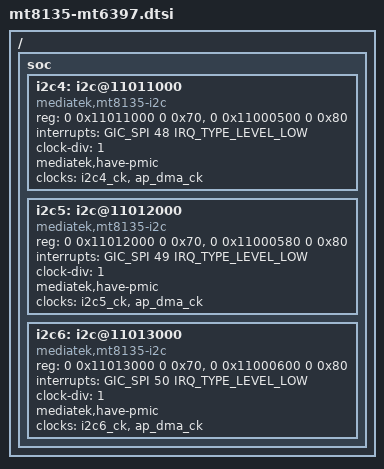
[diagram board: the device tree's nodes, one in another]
/*
 * Copyright (c) 2014 MediaTek Inc.
 * Author: Joe.C <yingjoe.chen@mediatek.com>
 *
 * This program is free software; you can redistribute it and/or modify
 * it under the terms of the GNU General Public License version 2 as
 * published by the Free Software Foundation.
 *
 * This program is distributed in the hope that it will be useful,
 * but WITHOUT ANY WARRANTY; without even the implied warranty of
 * MERCHANTABILITY or FITNESS FOR A PARTICULAR PURPOSE.  See the
 * GNU General Public License for more details.
 */

/ {
	soc {
		i2c4: i2c@11011000 {
			compatible = "mediatek,mt8135-i2c",
				"mediatek,mt6577-i2c";
			reg = <0 0x11011000 0 0x70>,
				<0 0x11000500 0 0x80>;
			interrupts = <GIC_SPI 48 IRQ_TYPE_LEVEL_LOW>;
			clock-div = <1>;
			mediatek,have-pmic;
			clocks = <&i2c4_ck>, <&ap_dma_ck>;
			clock-names = "main", "dma";
		};

		i2c5: i2c@11012000 {
			compatible = "mediatek,mt8135-i2c",
				"mediatek,mt6577-i2c";
			reg = <0 0x11012000 0 0x70>,
				<0 0x11000580 0 0x80>;
			interrupts = <GIC_SPI 49 IRQ_TYPE_LEVEL_LOW>;
			clock-div = <1>;
			mediatek,have-pmic;
			clocks = <&i2c5_ck>, <&ap_dma_ck>;
			clock-names = "main", "dma";
		};

		i2c6: i2c@11013000 {
			compatible = "mediatek,mt8135-i2c",
				"mediatek,mt6577-i2c";
			reg = <0 0x11013000 0 0x70>,
				<0 0x11000600 0 0x80>;
			interrupts = <GIC_SPI 50 IRQ_TYPE_LEVEL_LOW>;
			clock-div = <1>;
			mediatek,have-pmic;
			clocks = <&i2c6_ck>, <&ap_dma_ck>;
			clock-names = "main", "dma";
		};
	};
};
